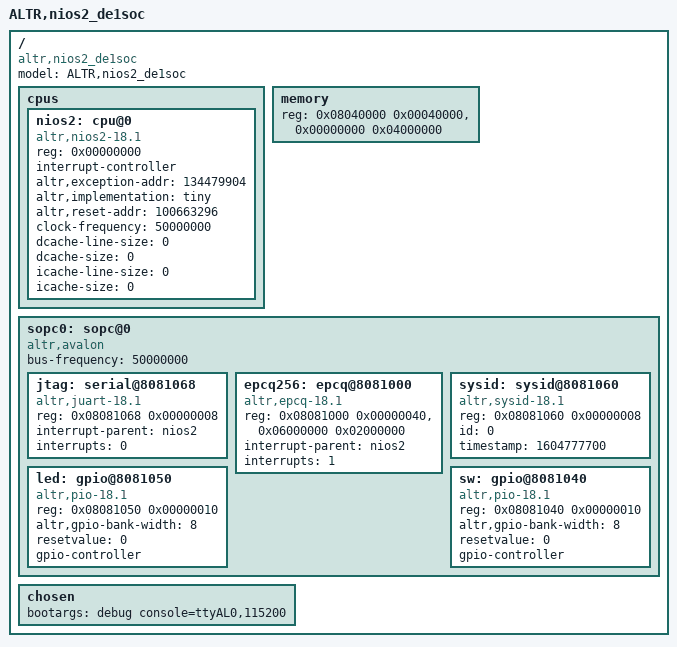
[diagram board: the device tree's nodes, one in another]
/*
 * This devicetree is generated by sopc2dts version rel_14.0_RC3-46-g25a6d58 on Sat Nov 07 22:57:01 CET 2020
 * Sopc2dts is written by Walter Goossens <waltergoossens@home.nl>
 * in cooperation with the nios2 community <nios2-dev@lists.rocketboards.org>
 */
/dts-v1/;

/ {
	model = "ALTR,nios2_de1soc";
	compatible = "altr,nios2_de1soc";
	#address-cells = <1>;
	#size-cells = <1>;

	cpus {
		#address-cells = <1>;
		#size-cells = <0>;

		nios2: cpu@0 {
			device_type = "cpu";
			compatible = "altr,nios2-18.1", "altr,nios2-1.1";
			reg = <0x00000000>;
			interrupt-controller;
			#interrupt-cells = <1>;
			altr,exception-addr = <134479904>;	/* embeddedsw.dts.params.altr,exception-addr type NUMBER */
			altr,implementation = "tiny";	/* embeddedsw.dts.params.altr,implementation type STRING */
			altr,reset-addr = <100663296>;	/* embeddedsw.dts.params.altr,reset-addr type NUMBER */
			clock-frequency = <50000000>;	/* embeddedsw.dts.params.clock-frequency type NUMBER */
			dcache-line-size = <0>;	/* embeddedsw.dts.params.dcache-line-size type NUMBER */
			dcache-size = <0>;	/* embeddedsw.dts.params.dcache-size type NUMBER */
			icache-line-size = <0>;	/* embeddedsw.dts.params.icache-line-size type NUMBER */
			icache-size = <0>;	/* embeddedsw.dts.params.icache-size type NUMBER */
		}; //end cpu@0 (nios2)
	}; //end cpus

	memory {
		device_type = "memory";
		reg = <0x08040000 0x00040000>,
			<0x00000000 0x04000000>;
	}; //end memory

	sopc0: sopc@0 {
		device_type = "soc";
		ranges;
		#address-cells = <1>;
		#size-cells = <1>;
		compatible = "altr,avalon", "simple-bus";
		bus-frequency = <50000000>;

		jtag: serial@8081068 {
			compatible = "altr,juart-18.1", "altr,juart-1.0";
			reg = <0x08081068 0x00000008>;
			interrupt-parent = <&nios2>;
			interrupts = <0>;
		}; //end serial@8081068 (jtag)

		epcq256: epcq@8081000 {
			compatible = "altr,epcq-18.1", "altr,epcq-1.0";
			reg = <0x08081000 0x00000040>,
				<0x06000000 0x02000000>;
			reg-names = "avl_csr", "avl_mem";
			interrupt-parent = <&nios2>;
			interrupts = <1>;
		}; //end epcq@8081000 (epcq256)

		sysid: sysid@8081060 {
			compatible = "altr,sysid-18.1", "altr,sysid-1.0";
			reg = <0x08081060 0x00000008>;
			id = <0>;	/* embeddedsw.dts.params.id type NUMBER */
			timestamp = <1604777700>;	/* embeddedsw.dts.params.timestamp type NUMBER */
		}; //end sysid@8081060 (sysid)

		led: gpio@8081050 {
			compatible = "altr,pio-18.1", "altr,pio-1.0";
			reg = <0x08081050 0x00000010>;
			altr,gpio-bank-width = <8>;	/* embeddedsw.dts.params.altr,gpio-bank-width type NUMBER */
			resetvalue = <0>;	/* embeddedsw.dts.params.resetvalue type NUMBER */
			#gpio-cells = <2>;
			gpio-controller;
		}; //end gpio@8081050 (led)

		sw: gpio@8081040 {
			compatible = "altr,pio-18.1", "altr,pio-1.0";
			reg = <0x08081040 0x00000010>;
			altr,gpio-bank-width = <8>;	/* embeddedsw.dts.params.altr,gpio-bank-width type NUMBER */
			resetvalue = <0>;	/* embeddedsw.dts.params.resetvalue type NUMBER */
			#gpio-cells = <2>;
			gpio-controller;
		}; //end gpio@8081040 (sw)
	}; //end sopc@0 (sopc0)

	chosen {
		bootargs = "debug console=ttyAL0,115200";
	}; //end chosen
}; //end /
